# xxvethernet register map
File version: 4.1
xxvethernet device descript
Registers are 32-bit, read-write, reset 0x0 unless marked. A register's access mark holds for its fields unless they carry their own. Offsets are from the block's base; lines under a group give offsets from that group; [hi:lo] are bit positions; {n}, {i} and the like mark numbered series; 'fields as' and 'values as' point back to an identical list; <NAME> marks a mode.

## Memory map
0x60110000 XXV_ETHERNET size 0x10000 — XXV Ethernet MAC

## XXV_ETHERNET — XXV Ethernet MAC
Base 0x60110000
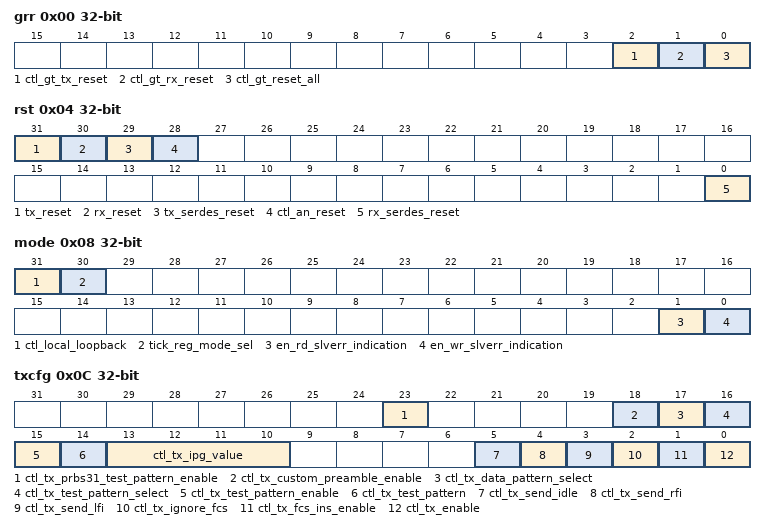
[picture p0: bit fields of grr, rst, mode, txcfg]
0x00 grr — GT Reset Register
  [all] fields
    0=DISABLE; 1=ENABLE
  [2] ctl_gt_tx_reset
  [1] ctl_gt_rx_reset
  [0] ctl_gt_reset_all
0x04 rst — Reset Register
  [all] fields
    0=DISABLE; 1=ENABLE
  [31] tx_reset
  [30] rx_reset
  [29] tx_serdes_reset
  [28] ctl_an_reset
  [0] rx_serdes_reset
0x08 mode
  [all] fields
    0=DISABLE; 1=ENABLE
  [31] ctl_local_loopback
  [30] tick_reg_mode_sel
  [1] en_rd_slverr_indication
  [0] en_wr_slverr_indication
0x0C txcfg — Tx Configuration Register
  [23] ctl_tx_prbs31_test_pattern_enable
    0=DISABLE; 1=ENABLE
  [18] ctl_tx_custom_preamble_enable
    0=DISABLE; 1=ENABLE
  [17] ctl_tx_data_pattern_select
    0=DISABLE; 1=ENABLE
  [16] ctl_tx_test_pattern_select
    0=DISABLE; 1=ENABLE
  [15] ctl_tx_test_pattern_enable
    0=DISABLE; 1=ENABLE
  [14] ctl_tx_test_pattern
    0=DISABLE; 1=ENABLE
  [13:10] ctl_tx_ipg_value
  [5] ctl_tx_send_idle
    0=DISABLE; 1=ENABLE
  [4] ctl_tx_send_rfi
    0=DISABLE; 1=ENABLE
  [3] ctl_tx_send_lfi
    0=DISABLE; 1=ENABLE
  [2] ctl_tx_ignore_fcs
    0=DISABLE; 1=ENABLE
  [1] ctl_tx_fcs_ins_enable
    0=DISABLE; 1=ENABLE
  [0] ctl_tx_enable
    0=DISABLE; 1=ENABLE
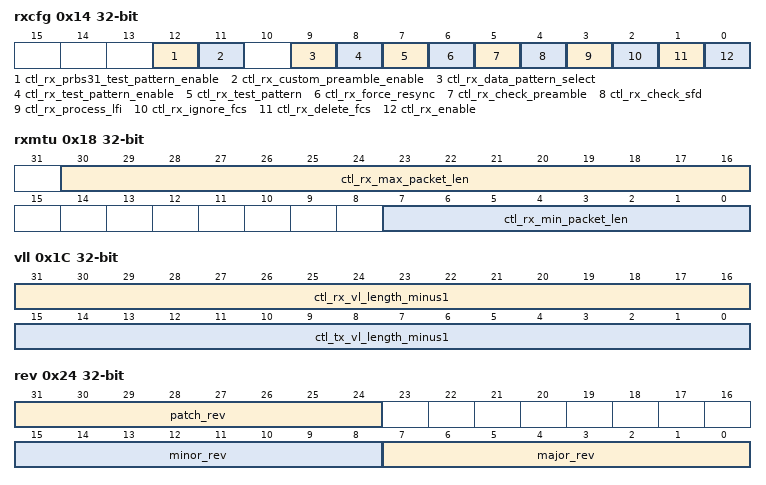
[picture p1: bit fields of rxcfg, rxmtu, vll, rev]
0x14 rxcfg — Rx Configuration Register
  [all] fields
    0=DISABLE; 1=ENABLE
  [12] ctl_rx_prbs31_test_pattern_enable
  [11] ctl_rx_custom_preamble_enable
  [9] ctl_rx_data_pattern_select
  [8] ctl_rx_test_pattern_enable
  [7] ctl_rx_test_pattern
  [6] ctl_rx_force_resync
  [5] ctl_rx_check_preamble
  [4] ctl_rx_check_sfd
  [3] ctl_rx_process_lfi
  [2] ctl_rx_ignore_fcs
  [1] ctl_rx_delete_fcs
  [0] ctl_rx_enable
0x18 rxmtu — Rx MTU Configuration Register
  [30:16] ctl_rx_max_packet_len, [7:0] ctl_rx_min_packet_len
0x1C vll — VL Length Configuration Register
  [31:16] ctl_rx_vl_length_minus1, [15:0] ctl_tx_vl_length_minus1
0x20 tick wo
  [0] tick_reg
0x24 rev ro — Revision Register
  [31:24] patch_rev, [15:8] minor_rev, [7:0] major_rev
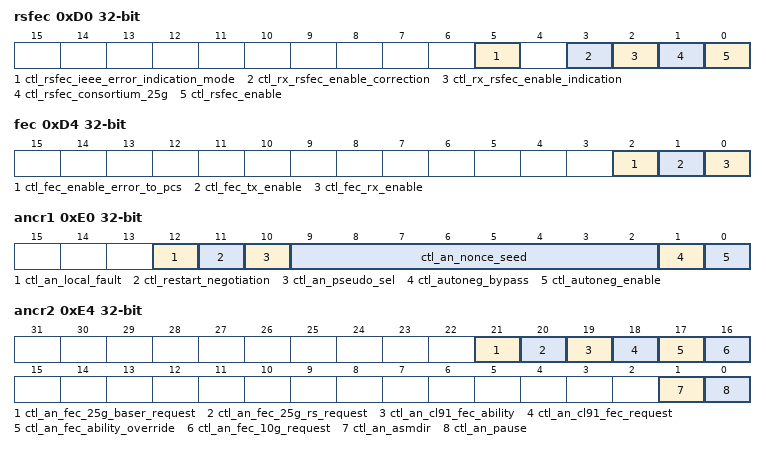
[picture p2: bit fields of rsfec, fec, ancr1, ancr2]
0xD0 rsfec — Refec Register
  [all] fields
    0=DISABLE; 1=ENABLE
  [5] ctl_rsfec_ieee_error_indication_mode
  [3] ctl_rx_rsfec_enable_correction
  [2] ctl_rx_rsfec_enable_indication
  [1] ctl_rsfec_consortium_25g
  [0] ctl_rsfec_enable
0xD4 fec
  [all] fields
    0=DISABLE; 1=ENABLE
  [2] ctl_fec_enable_error_to_pcs
  [1] ctl_fec_tx_enable
  [0] ctl_fec_rx_enable
0xE0 ancr1 — AN_CONTROL1 Configuration Register
  [12] ctl_an_local_fault
    0=DISABLE; 1=ENABLE
  [11] ctl_restart_negotiation
    0=DISABLE; 1=ENABLE
  [10] ctl_an_pseudo_sel
    0=DISABLE; 1=ENABLE
  [9:2] ctl_an_nonce_seed
  [1] ctl_autoneg_bypass
    0=DISABLE; 1=ENABLE
  [0] ctl_autoneg_enable
    0=DISABLE; 1=ENABLE
0xE4 ancr2 — AN_CONTROL2 Configuration Register
  [all] fields
    0=DISABLE; 1=ENABLE
  [21] ctl_an_fec_25g_baser_request
  [20] ctl_an_fec_25g_rs_request
  [19] ctl_an_cl91_fec_ability
  [18] ctl_an_cl91_fec_request
  [17] ctl_an_fec_ability_override
  [16] ctl_an_fec_10g_request
  [1] ctl_an_asmdir
  [0] ctl_an_pause
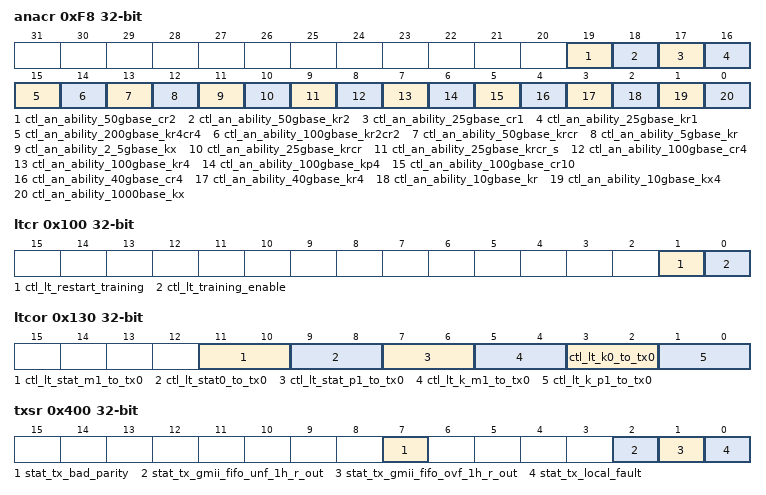
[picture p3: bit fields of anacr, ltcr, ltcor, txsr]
0xF8 anacr — AN_ABILITY Configuration Register
  [all] fields
    0=DISABLE; 1=ENABLE
  [19] ctl_an_ability_50gbase_cr2
  [18] ctl_an_ability_50gbase_kr2
  [17] ctl_an_ability_25gbase_cr1
  [16] ctl_an_ability_25gbase_kr1
  [15] ctl_an_ability_200gbase_kr4cr4
  [14] ctl_an_ability_100gbase_kr2cr2
  [13] ctl_an_ability_50gbase_krcr
  [12] ctl_an_ability_5gbase_kr
  [11] ctl_an_ability_2_5gbase_kx
  [10] ctl_an_ability_25gbase_krcr
  [9] ctl_an_ability_25gbase_krcr_s
  [8] ctl_an_ability_100gbase_cr4
  [7] ctl_an_ability_100gbase_kr4
  [6] ctl_an_ability_100gbase_kp4
  [5] ctl_an_ability_100gbase_cr10
  [4] ctl_an_ability_40gbase_cr4
  [3] ctl_an_ability_40gbase_kr4
  [2] ctl_an_ability_10gbase_kr
  [1] ctl_an_ability_10gbase_kx4
  [0] ctl_an_ability_1000base_kx
0x100 ltcr — LT_CONTROL Configuration Register
  [1] ctl_lt_restart_training
    0=DISABLE; 1=ENABLE
  [0] ctl_lt_training_enable
    0=DISABLE; 1=ENABLE
0x104 lttr — LT_TRAINED Configuration Register
  [0] ctl_lt_rx_trained
    0=DISABLE; 1=ENABLE
0x108 ltpr — LT_PRESET Configuration Register
  [0] ctl_lt_preset_to_tx
    0=DISABLE; 1=ENABLE
0x10C ltir — LT_INIT Configuration Register
  [0] ctl_lt_initialize_to_tx
    0=DISABLE; 1=ENABLE
0x110 ltsr — LT_SEED Configuration Register
  [10:0] ctl_lt_pseudo_seed0
0x130 ltcor — LT_COEFFICIENT Configuration Register
  [11:10] ctl_lt_stat_m1_to_tx0, [9:8] ctl_lt_stat0_to_tx0, [7:6] ctl_lt_stat_p1_to_tx0, [5:4] ctl_lt_k_m1_to_tx0, [3:2] ctl_lt_k0_to_tx0, [1:0] ctl_lt_k_p1_to_tx0
0x400 txsr ro — Stat TX Status Register
  [all] fields
    0=DISABLE; 1=ENABLE
  [7] stat_tx_bad_parity
  [2] stat_tx_gmii_fifo_unf_1h_r_out
  [1] stat_tx_gmii_fifo_ovf_1h_r_out
  [0] stat_tx_local_fault
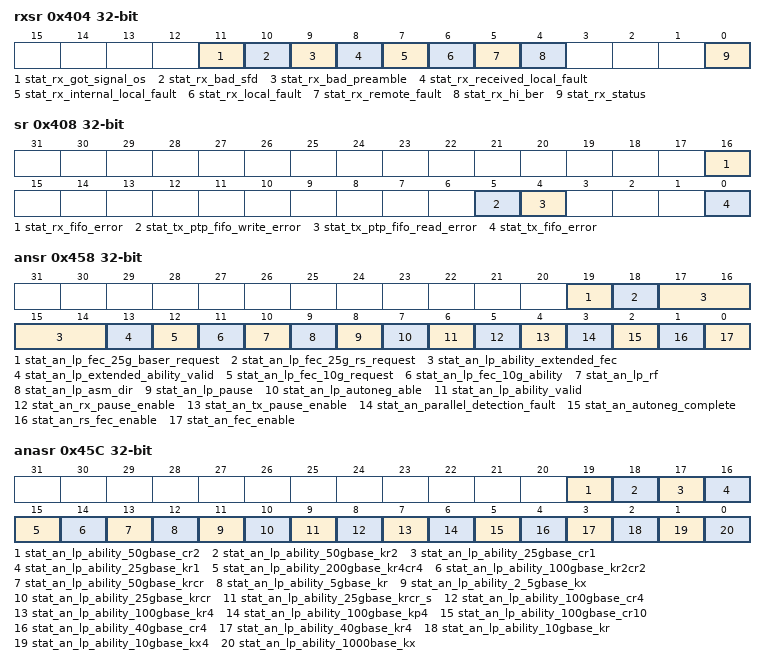
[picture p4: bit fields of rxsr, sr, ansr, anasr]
0x404 rxsr ro — Stat RX Status Register
  [all] fields
    0=DISABLE; 1=ENABLE
  [11] stat_rx_got_signal_os
  [10] stat_rx_bad_sfd
  [9] stat_rx_bad_preamble
  [8] stat_rx_received_local_fault
  [7] stat_rx_internal_local_fault
  [6] stat_rx_local_fault
  [5] stat_rx_remote_fault
  [4] stat_rx_hi_ber
  [0] stat_rx_status
0x408 sr ro — Stat Status Register
  [all] fields
    0=DISABLE; 1=ENABLE
  [16] stat_rx_fifo_error
  [5] stat_tx_ptp_fifo_write_error
  [4] stat_tx_ptp_fifo_read_error
  [0] stat_tx_fifo_error
0x40C rxblsr ro — Stat RX Block Lock Register
  [0] stat_rx_block_lock
    0=DISABLE; 1=ENABLE
0x458 ansr ro — Stat AN_STATUS Register
  [19] stat_an_lp_fec_25g_baser_request
    0=DISABLE; 1=ENABLE
  [18] stat_an_lp_fec_25g_rs_request
    0=DISABLE; 1=ENABLE
  [17:14] stat_an_lp_ability_extended_fec
  [13] stat_an_lp_extended_ability_valid
    0=DISABLE; 1=ENABLE
  [12] stat_an_lp_fec_10g_request
    0=DISABLE; 1=ENABLE
  [11] stat_an_lp_fec_10g_ability
    0=DISABLE; 1=ENABLE
  [10] stat_an_lp_rf
    0=DISABLE; 1=ENABLE
  [9] stat_an_lp_asm_dir
    0=DISABLE; 1=ENABLE
  [8] stat_an_lp_pause
    0=DISABLE; 1=ENABLE
  [7] stat_an_lp_autoneg_able
    0=DISABLE; 1=ENABLE
  [6] stat_an_lp_ability_valid
    0=DISABLE; 1=ENABLE
  [5] stat_an_rx_pause_enable
    0=DISABLE; 1=ENABLE
  [4] stat_an_tx_pause_enable
    0=DISABLE; 1=ENABLE
  [3] stat_an_parallel_detection_fault
    0=DISABLE; 1=ENABLE
  [2] stat_an_autoneg_complete
    0=DISABLE; 1=ENABLE
  [1] stat_an_rs_fec_enable
    0=DISABLE; 1=ENABLE
  [0] stat_an_fec_enable
    0=DISABLE; 1=ENABLE
0x45C anasr ro — Stat AN_ABILITY Register
  [all] fields
    0=DISABLE; 1=ENABLE
  [19] stat_an_lp_ability_50gbase_cr2
  [18] stat_an_lp_ability_50gbase_kr2
  [17] stat_an_lp_ability_25gbase_cr1
  [16] stat_an_lp_ability_25gbase_kr1
  [15] stat_an_lp_ability_200gbase_kr4cr4
  [14] stat_an_lp_ability_100gbase_kr2cr2
  [13] stat_an_lp_ability_50gbase_krcr
  [12] stat_an_lp_ability_5gbase_kr
  [11] stat_an_lp_ability_2_5gbase_kx
  [10] stat_an_lp_ability_25gbase_krcr
  [9] stat_an_lp_ability_25gbase_krcr_s
  [8] stat_an_lp_ability_100gbase_cr4
  [7] stat_an_lp_ability_100gbase_kr4
  [6] stat_an_lp_ability_100gbase_kp4
  [5] stat_an_lp_ability_100gbase_cr10
  [4] stat_an_lp_ability_40gbase_cr4
  [3] stat_an_lp_ability_40gbase_kr4
  [2] stat_an_lp_ability_10gbase_kr
  [1] stat_an_lp_ability_10gbase_kx4
  [0] stat_an_lp_ability_1000base_kx
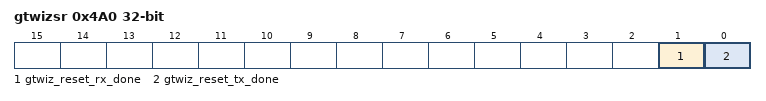
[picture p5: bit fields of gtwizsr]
0x4A0 gtwizsr ro — Stat GT_WIZ Register
  [1] gtwiz_reset_rx_done
    0=DISABLE; 1=ENABLE
  [0] gtwiz_reset_tx_done
    0=DISABLE; 1=ENABLE
